# CY8C5868LTI_LP039 register map
File version: 0.1
CY8C58LP
Registers are 8-bit, read-write, no defined reset value unless marked. A register's access mark holds for its fields unless they carry their own. Offsets are from the block's base; lines under a group give offsets from that group; [hi:lo] are bit positions; {n}, {i} and the like mark numbered series; 'fields as' and 'values as' point back to an identical list; <NAME> marks a mode.

## Memory map
0x00000000 N_UART — UART
0x00000000 Sup_I2C
0x00000000 USB — USBFS
0x00000000 SysTimer
0x00000000 P_UART — UART
0x00000000 SuspendWD — Count7 debug registers

## N_UART — UART
Base 0x00000000
0x40006441 TX_N_UART_TX_DATA — TX Data Register
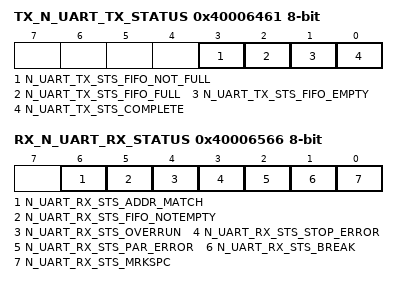
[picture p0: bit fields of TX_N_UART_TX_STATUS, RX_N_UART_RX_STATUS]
0x40006461 TX_N_UART_TX_STATUS — TX status register
  [3] N_UART_TX_STS_FIFO_NOT_FULL ro, [2] N_UART_TX_STS_FIFO_FULL ro, [1] N_UART_TX_STS_FIFO_EMPTY ro, [0] N_UART_TX_STS_COMPLETE ro
0x40006524 RX_N_UART_RX_ADDRESS1 — RX Address1 Register
0x40006534 RX_N_UART_RX_ADDRESS2 — RX Address2 Register
0x40006544 RX_N_UART_RX_DATA — RX Data Register
0x40006566 RX_N_UART_RX_STATUS — RX status register
  [6] N_UART_RX_STS_ADDR_MATCH ro, [5] N_UART_RX_STS_FIFO_NOTEMPTY ro, [4] N_UART_RX_STS_OVERRUN ro, [3] N_UART_RX_STS_STOP_ERROR ro, [2] N_UART_RX_STS_PAR_ERROR ro, [1] N_UART_RX_STS_BREAK ro, [0] N_UART_RX_STS_MRKSPC ro

## SysTimer
Base 0x00000000
0x40006406 SysTimer_COUNTER — UDB.A0 - Current Down Counter Value
0x40006426 SysTimer_PERIOD — UDB.D0 - Assigned Period
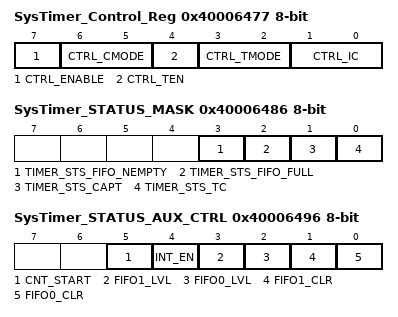
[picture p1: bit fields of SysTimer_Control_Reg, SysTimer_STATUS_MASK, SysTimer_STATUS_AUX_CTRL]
0x40006477 SysTimer_Control_Reg — UDB Control Register - Assigned Control Register Value
  [7] CTRL_ENABLE — Enable the Timer
  [6:5] CTRL_CMODE — Capture Mode
  [4] CTRL_TEN — Trigger Enable Bit
  [3:2] CTRL_TMODE — Trigger Mode
  [1:0] CTRL_IC — Interrupt Count
0x40006486 SysTimer_STATUS_MASK — UDB Status bits Interrupt Mask Enable Register
  [3] TIMER_STS_FIFO_NEMPTY ro — FIFO Empty status
  [2] TIMER_STS_FIFO_FULL ro — FIFO Full Status
  [1] TIMER_STS_CAPT ro — Enables the Interrupt on Capture
  [0] TIMER_STS_TC ro — Enables the Interrupt on TC
0x40006496 SysTimer_STATUS_AUX_CTRL — UDB Auxilliary Control Register
  [5] CNT_START — FIFO0 clear
    0=E_CNT_START0 (Disable counter); 1=E_CNT_START1 (Enable counter)
  [4] INT_EN
    0=E_INT_EN0 (Interrupt disabled); 1=E_INT_EN1 (Interrupt enabled)
  [3] FIFO1_LVL — FIFO level
    0=E_FIFO_LVL_0 (FIFO LVL: input mode: FIFO not full; output mode: FIFO not empty); 1=E_FIFO_LVL_1 (FIFO LVL: input mode: FIFO at least 1/2 empty; output mode: FIFO at least 1/2 full)
  [2] FIFO0_LVL — FIFO level
    values as FIFO1_LVL
  [1] FIFO1_CLR — FIFO1 clear
    0=E_FIFO_CLR_0 (Normal FIFO operation); 1=E_FIFO_CLR_1 (Clear FIFO state)
  [0] FIFO0_CLR — FIFO0 clear
    values as FIFO1_CLR

## P_UART — UART
Base 0x00000000
0x40006424 RX_P_UART_RX_ADDRESS1 — RX Address1 Register
0x40006434 RX_P_UART_RX_ADDRESS2 — RX Address2 Register
0x40006440 TX_P_UART_TX_DATA — TX Data Register
0x40006444 RX_P_UART_RX_DATA — RX Data Register
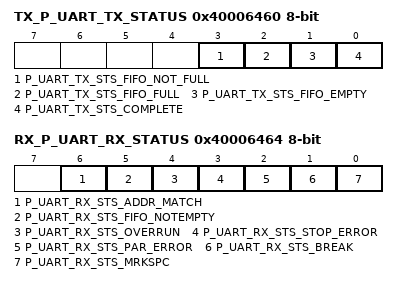
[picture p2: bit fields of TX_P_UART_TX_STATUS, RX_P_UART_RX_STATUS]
0x40006460 TX_P_UART_TX_STATUS — TX status register
  [3] P_UART_TX_STS_FIFO_NOT_FULL ro, [2] P_UART_TX_STS_FIFO_FULL ro, [1] P_UART_TX_STS_FIFO_EMPTY ro, [0] P_UART_TX_STS_COMPLETE ro
0x40006464 RX_P_UART_RX_STATUS — RX status register
  [6] P_UART_RX_STS_ADDR_MATCH ro, [5] P_UART_RX_STS_FIFO_NOTEMPTY ro, [4] P_UART_RX_STS_OVERRUN ro, [3] P_UART_RX_STS_STOP_ERROR ro, [2] P_UART_RX_STS_PAR_ERROR ro, [1] P_UART_RX_STS_BREAK ro, [0] P_UART_RX_STS_MRKSPC ro

## SuspendWD — Count7 debug registers
Base 0x00000000
0x40006473 COUNT 7-bit — Count value register
0x40006483 PERIOD 7-bit — Count7 period register
